# M0519AE_v1 register map
File version: 1.0
Registers are 32-bit, read-write, reset 0x0 unless marked. A register's access mark holds for its fields unless they carry their own. Offsets are from the block's base; [hi:lo] are bit positions; {n}, {i} and the like mark numbered series.

## UART0 — UART Register Map
Base 0x40050000
Same registers: UART1 0x40150000
0x00 UA_RBR ro reset not defined — UART Receive Buffer Register
  [7:0] RBR — Receive Buffer Register (Read Only). By reading this register, the UART will return an 8-bit data received from UART_RXD pin (LSB first).
0x00 UA_THR wo reset not defined (alternate view of UA_RBR) — UART Transmit Holding Register
  [7:0] THR — Transmit Holding Register. By writing one byte to this register, the data byte will be stored in transmitter FIFO. The UART Controller will send out the data stored in transmitter FIFO top location through the UART_TXD pin. (LSB first)
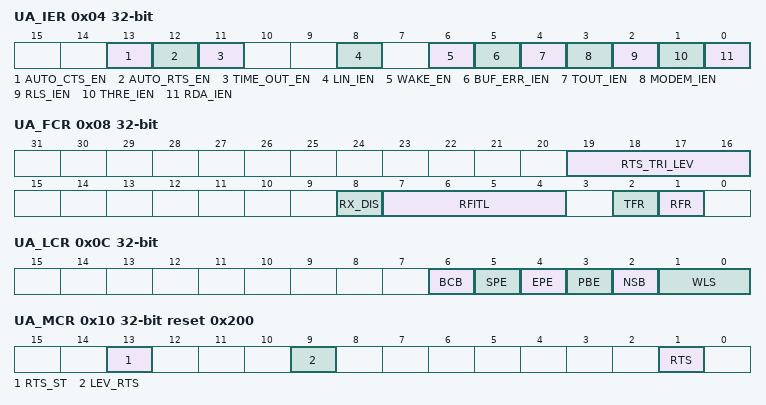
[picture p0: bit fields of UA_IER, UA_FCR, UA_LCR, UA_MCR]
0x04 UA_IER — UART Interrupt Enable Register
  [13] AUTO_CTS_EN — nCTS Auto Flow Control Enable Bit. When nCTS auto-flow is enabled, the UART will send data to external device when nCTS input assert (UART will not send data to device until nCTS is asserted).
    0=nCTS auto-flow control Disabled; 1=nCTS auto-flow control Enabled
  [12] AUTO_RTS_EN — nRTS Auto Flow Control Enable Bit. When nRTS auto-flow is enabled, if the number of bytes in the RX FIFO equals the RTS_TRI_LEV (UA_FCR[19:16]), the UART will de-assert nRTS signal.
    0=nRTS auto-flow control Disabled; 1=nRTS auto-flow control Enabled
  [11] TIME_OUT_EN — Receive Buffer Time Out Counter Enable Bit
    0=Receive Buffer time out counter Disabled; 1=Receive Buffer time out counter Enabled
  [8] LIN_IEN — LIN Bus Interrupt Enable Bit. Note: This field is used for LIN function mode.
    0=Lin bus interrupt Disabled; 1=Lin bus interrupt Enabled
  [6] WAKE_EN — UART Wake-up Function Enable Bit
    0=UART wake-up function Disabled; 1=UART wake-up function Enabled, when the chip is in Power-down mode, an external nCTS change will wake-up chip from Power-down mode
  [5] BUF_ERR_IEN — Buffer Error Interrupt Enable Bit
    0=Buffer error interrupt Disabled; 1=Buffer error interrupt Enabled
  [4] TOUT_IEN — RX Time Out Interrupt Enable Bit
    0=RX time-out interrupt Disabled; 1=RX time-out interrupt Enabled
  [3] MODEM_IEN — Modem Status Interrupt Enable Bit
    0=Modem status interrupt Disabled; 1=Modem status interrupt Enabled
  [2] RLS_IEN — Receive Line Status Interrupt Enable Bit
    0=Receive Line Status interrupt Disabled; 1=Receive Line Status interrupt Enabled
  [1] THRE_IEN — Transmit Holding Register Empty Interrupt Enable Bit
    0=Transmit holding register empty interrupt Disabled; 1=Transmit holding register empty interrupt Enabled
  [0] RDA_IEN — Receive Data Available Interrupt Enable Bit
    0=Receive data available interrupt Disabled; 1=Receive data available interrupt Enabled
0x08 UA_FCR — UART FIFO Control Register
  [19:16] RTS_TRI_LEV — nRTS Trigger Level for Auto-flow Control Use. Note: This field is used for auto nRTS flow control.
    0=nRTS Trigger Level is 1 byte; 1=nRTS Trigger Level is 4 bytes; 2=nRTS Trigger Level is 8 bytes; 3=nRTS Trigger Level is 14 bytes
  [8] RX_DIS — Receiver Disable Register. The receiver is disabled or not (set 1 to disable receiver). Note: This field is used for RS-485 Normal Multi-drop mode. It should be programmed before RS485_NMM (UA_ALT_CSR [8]) is programmed.
    0=Receiver Enabled; 1=Receiver Disabled
  [7:4] RFITL — RX FIFO Interrupt Trigger Level. When the number of bytes in the receive FIFO equals the RFITL, the RDA_IF will be set (if RDA_IEN(UA_IER [0]) enabled, and an interrupt will be generated).
    0=RX FIFO Interrupt Trigger Level is 1 byte; 1=RX FIFO Interrupt Trigger Level is 4 bytes; 2=RX FIFO Interrupt Trigger Level is 8 bytes; 3=RX FIFO Interrupt Trigger Level is 14 bytes
  [2] TFR — TX Field Software Reset. When TFR is set, all the byte in the transmit FIFO and TX internal state machine are cleared. Note: This bit will automatically clear at least 3 UART engine clock cycles.
    0=No effect; 1=Reset the TX internal state machine and pointers
  [1] RFR — RX Field Software Reset. When RFR is set, all the byte in the receiver FIFO and RX internal state machine are cleared. Note: This bit will automatically clear at least 3 UART engine clock cycles.
    0=No effect; 1=Reset the RX internal state machine and pointers
0x0C UA_LCR — UART Line Control Register
  [6] BCB — Break Control Bit. Note: When this bit is set to logic 1, the serial data output (TX) is forced to the Spacing State (logic 0). This bit acts only on TX and has no effect on the transmitter logic.
    0=Break Control Disabled; 1=Break Control Enabled
  [5] SPE — Stick Parity Enable Bit. Note: If PBE (UA_LCR[3]) and EBE (UA_LCR[4]) are logic 1, the parity bit is transmitted and checked as logic 0. If PBE (UA_LCR[3]) is 1 and EBE (UA_LCR[4]) is 0 then the parity bit is transmitted and checked as 1.
    0=Stick parity Disabled; 1=Stick parity Enabled
  [4] EPE — Even Parity Enable Bit. Note: This bit has effect only when PBE (UA_LCR[3]) is set.
    0=Odd number of logic 1's is transmitted and checked in each word; 1=Even number of logic 1's is transmitted and checked in each word
  [3] PBE — Parity Bit Enable Bit. Note: Parity bit is generated on each outgoing character and is checked on each incoming data.
    0=No parity bit; 1=Parity bit generated Enabled
  [2] NSB — Number of "STOP Bit"
    0=One " STOP bit" is generated in the transmitted data; 1=When select 5-bit word length, 1.5 "STOP bit" is generated in the transmitted data. When select 6-,7- and 8-bit word length, 2 "STOP bit" is generated in the transmitted data
  [1:0] WLS — Word Length Selection
    {v}=character length is {v+5}-bit (v=0..3)
0x10 UA_MCR reset 0x200 — UART Modem Control Register
  [13] RTS_ST ro — nRTS Pin State (Read Only). This bit mirror from nRTS pin output of voltage logic status.
    0=nRTS pin output is low level voltage logic state; 1=nRTS pin output is high level voltage logic state
  [9] LEV_RTS — nRTS Pin Active Level. This bit defines the active level state of nRTS pin output. Note1: Refer to Figure 678 and Figure 679 for UART function mode. Note2: Refer to Figure 682 and Figure 683 for RS-485 function mode.
    0=nRTS pin output is high level active; 1=nRTS pin output is low level active. (Default)
  [1] RTS — nRTS (Request-to-send) Signal. This bit is direct control internal nRTS signal active or not, and then drive the nRTS pin output with LEV_RTS bit configuration. Note1: This nRTS signal control bit is not effective when nRTS auto-flow control is enabled in UART function mode. Note2: This nRTS signal control bit is not effective when RS-485 auto direction mode (AUD) is enabled in RS-485 function mode.
    0=nRTS signal is active; 1=nRTS signal is inactive
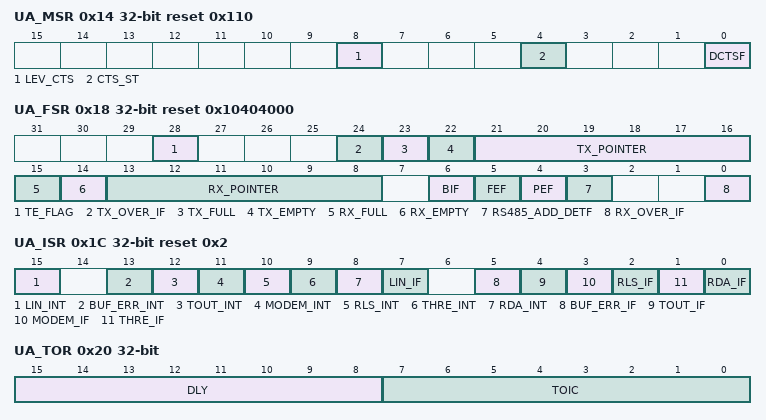
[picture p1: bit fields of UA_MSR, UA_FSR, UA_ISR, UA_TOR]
0x14 UA_MSR reset 0x110 — UART Modem Status Register
  [8] LEV_CTS — nCTS Pin Active Level. This bit defines the active level state of nCTS pin input.
    0=nCTS pin input is high level active; 1=nCTS pin input is low level active. (Default)
  [4] CTS_ST ro — nCTS Pin Status (Read Only). This bit mirror from nCTS pin input of voltage logic status. Note: This bit echoes when UART Controller peripheral clock is enabled, and nCTS multi-function port is selected.
    0=nCTS pin input is low level voltage logic state; 1=nCTS pin input is low level voltage logic state
  [0] DCTSF — Detect nCTS State Change Flag. This bit is set whenever nCTS input has change state, and it will generate Modem interrupt to CPU when MODEM_IEN (UA_IER[3]) is set to 1. Write 1 to clear this bit to 0
0x18 UA_FSR reset 0x10404000 — UART FIFO Status Register
  [28] TE_FLAG ro — Transmitter Empty Flag (Read Only). This bit is set by hardware when TX FIFO (UA_THR) is empty and the STOP bit of the last byte has been transmitted. Note: This bit is cleared automatically when TX FIFO is not empty or the last byte transmission has not completed.
    0=TX FIFO is not empty or the STOP bit of the last byte has not been transmitted; 1=TX FIFO is empty and the STOP bit of the last byte has been transmitted
  [24] TX_OVER_IF — TX Overflow Error Interrupt Flag. If TX FIFO (UA_THR) is full, an additional write to UA_THR will cause this bit to logic 1. Note: This bit can be cleared by writing '1' to it.
    0=TX FIFO is not overflow; 1=TX FIFO is overflow
  [23] TX_FULL ro — Transmitter FIFO Full (Read Only). This bit indicates TX FIFO is full or not. Note: This bit is set when the number of usage in TX FIFO Buffer equal to 16, otherwise it is cleared by hardware.
    0=TX FIFO is not full; 1=TX FIFO is full
  [22] TX_EMPTY ro — Transmitter FIFO Empty (Read Only). This bit indicates TX FIFO is empty or not. Note: When the last byte of TX FIFO has been transferred to Transmitter Shift Register, hardware sets this bit high. It will be cleared when writing data into UA_THR (TX FIFO not empty).
    0=TX FIFO is not empty; 1=TX FIFO is empty
  [21:16] TX_POINTER ro — TX FIFO Pointer (Read Only). This field indicates the TX FIFO Buffer Pointer. When CPU writes one byte into UA_THR, TX_POINTER increases one. When one byte of TX FIFO is transferred to Transmitter Shift Register, TX_POINTER decreases one. The Maximum value shown in TX_POINTER is 15. When the using level of TX FIFO Buffer equal to 16, the TX_FULL bit is set to 1 and TX_POINTER will show 0. As one byte of TX FIFO is transferred to Transmitter Shift Register, the TX_FULL bit is cleared to 0 and TX_POINTER will show 15.
  [15] RX_FULL ro — Receiver FIFO Full (Read Only). This bit indicates RX FIFO is full or not. Note: This bit is set when the number of usage in RX FIFO Buffer is equal to 16, otherwise is cleared by hardware.
    0=RX FIFO is not full; 1=RX FIFO is full
  [14] RX_EMPTY ro — Receiver FIFO Empty (Read Only). This bit indicates RX FIFO empty or not. Note: When the last byte of RX FIFO has been read by CPU, hardware sets this bit high. It will be cleared when UART receives any new data.
    0=RX FIFO is not empty; 1=RX FIFO is empty
  [13:8] RX_POINTER ro — RX FIFO Pointer (Read Only). This field indicates the RX FIFO Buffer Pointer. When UART receives one byte from external device, RX_POINTER increases one. When one byte of RX FIFO is read by CPU, RX_POINTER decreases one. The Maximum value shown in RX_POINTER is 15. When the using level of RX FIFO Buffer equal to 16, the RX_FULL bit is set to 1 and RX_POINTER will show 0. As one byte of RX FIFO is read by CPU, the RX_FULL bit is cleared to 0 and RX_POINTER will show 15.
  [6] BIF — Break Error Interrupt Flag. This bit is set to a logic 1 whenever the received data input(RX) is held in the "spacing state" (logic 0) for longer than a full word transmission time (that is, the total time of "start bit" + data bits + parity + stop bits). Note: This bit can be cleared by writing '1' to it.
    0=No Break error is generated; 1=Break error is generated
  [5] FEF — Frame Error Flag. This bit is set to logic 1 whenever the received character does not have a valid "stop bit" (that is, the stop bit following the last data bit or parity bit is detected as a logic 0). Note: This bit can be cleared by writing '1' to it.
    0=No frame error is generated; 1=Frame error is generated
  [4] PEF — Parity Error Flag. This bit is set to logic 1 whenever the received character does not have a valid "parity bit" . Note: This bit can be cleared by writing '1' to it.
    0=No parity error is generated; 1=Parity error is generated
  [3] RS485_ADD_DETF — RS-485 Address Byte Detection Flag. Note1: This field is used for RS-485 function mode and RS485_ADD_EN (UA_ALT_CSR[15]) is set to 1 to enable Address detection mode. Note2: This bit can be cleared by writing '1' to it.
    0=Receiver detects a data that is not an address bit (bit 9 ='0'); 1=Receiver detects a data that is an address bit (bit 9 ='1')
  [0] RX_OVER_IF — RX Overflow Error Interrupt Flag. This bit is set when RX FIFO overflow. If the number of bytes of received data is greater than RX_FIFO (UA_RBR) size, this bit will be set. Note: This bit can be cleared by writing '1' to it.
    0=RX FIFO is not overflow; 1=RX FIFO is overflow
0x1C UA_ISR reset 0x2 — UART Interrupt Status Register
  [15] LIN_INT ro — LIN Bus Interrupt Indicator (Read Only). This bit is set if LIN_IEN (UA_IER[8]) and LIN _IF (UA_ISR[7]) are both set to 1.
    0=No LIN Bus interrupt is generated; 1=The LIN Bus interrupt is generated
  [13] BUF_ERR_INT ro — Buffer Error Interrupt Indicator (Read Only). This bit is set if BUF_ERR_IEN (UA_IER[5]) and BUF_ERR_IF (UA_ISR[5]) are both set to 1.
    0=No buffer error interrupt is generated; 1=Buffer error interrupt is generated
  [12] TOUT_INT ro — Time Out Interrupt Indicator (Read Only). This bit is set if TOUT_IEN (UA_IER[4]) and TOUT_IF (UA_ISR[4]) are both set to 1.
    0=No time-out interrupt is generated; 1=Time-out interrupt is generated
  [11] MODEM_INT ro — MODEM Status Interrupt Indicator (Read Only). This bit is set if MODEM_IEN (UA_IER[3]) and MODEM_IF (UA_ISR[3]) are both set to 1.
    0=No Modem interrupt is generated; 1=Modem interrupt is generated
  [10] RLS_INT ro — Receive Line Status Interrupt Indicator (Read Only). This bit is set if RLS_IEN (UA_IER[2] and RLS_IF (UA_ISR[2]) are both set to 1.
    0=No RLS interrupt is generated; 1=RLS interrupt is generated
  [9] THRE_INT ro — Transmit Holding Register Empty Interrupt Indicator (Read Only). This bit is set if THRE_IEN (UA_IER[1]) and THRE_IF (UA_ISR[1]) are both set to 1.
    0=No THRE interrupt is generated; 1=THRE interrupt is generated
  [8] RDA_INT ro — Receive Data Available Interrupt Indicator (Read Only). This bit is set if RDA_IEN (UA_IER[0]) and RDA_IF (UA_ISR[0]) are both set to 1.
    0=No RDA interrupt is generated; 1=RDA interrupt is generated
  [7] LIN_IF ro — LIN Bus Flag (Read Only). Note: This bit is read only. This bit is cleared when LINS_HDET_F (UA_LIN_SR[0]), LIN_BKDET_F (UA_LIN_SR[8]), BIT_ERR_F (UA_LIN_SR[9]), LINS_IDPENR_F (UA_LIN_SR[2]) and LINS_HERR_F (UA_LIN_SR[1]) all are cleared.
    0=None of LINS_HDET_F, LIN_BKDET_F, BIT_ERR_F, LINS_IDPERR_F and LINS_HERR_F is generated; 1=At least one of LINS_HDET_F, LIN_BKDET_F, BIT_ERR_F, LINS_IDPERR_F and LINS_HERR_F is generated
  [5] BUF_ERR_IF ro — Buffer Error Interrupt Flag (Read Only). This bit is set when the TX or RX FIFO overflows (TX_OVER_IF (UA_FSR[24]) or RX_OVER_IF (UA_FSR[0]) is set. When BUF_ERR_IF (UA_ISR[5]) is set, the transfer is not correct. If BUF_ERR_IEN (UA_IER [5]) is enabled, the buffer error interrupt will be generated. Note: This bit is cleared if both of RX_OVER_IF (UA_FSR[0]) and TX_OVER_IF (UA_FSR[24]) are cleared to 0 by writing 1 to RX_OVER_IF (UA_FSR[0]) and TX_OVER_IF (UA_FSR[24]).
    0=No buffer error interrupt flag is generated; 1=Buffer error interrupt flag is generated
  [4] TOUT_IF ro — Time Out Interrupt Flag (Read Only). This bit is set when the RX FIFO is not empty and no activities occurred in the RX FIFO and the time out counter equal to TOIC (UA_TOR[7:0]). If TOUT_IEN (UA_IER [4]) is enabled, the time-out interrupt will be generated. Note: User can read UA_RBR (RX is in active) to clear it.
    0=No Time-out interrupt flag is generated; 1=Time-out interrupt flag is generated
  [3] MODEM_IF ro — MODEM Interrupt Flag (Read Only). Note: This bit is reset to 0 when bit DCTSF (UA_MSR[0]) is cleared by a write 1 on DCTSF (UA_MSR[0]).
    0=No Modem interrupt flag is generated; 1=Modem interrupt flag is generated
  [2] RLS_IF ro — Receive Line Interrupt Flag (Read Only). This bit is set when the RX receive data have parity error, frame error or break error (at least one of 3 bits, BIF (UA_FSR[6]), FEF (UA_FSR[5]) and PEF (UA_FSR[4]), is set). If RLS_IEN (UA_IER [2]) is enabled, the RLS interrupt will be generated. Note2: This bit is read only and reset to 0 when all bits of BIF (UA_FSR[6]), FEF (UA_FSR[5]) and PEF (UA_FSR[4]) are cleared. Note3: In RS-485 function mode, this bit is read only and reset to 0 when all bits of BIF (UA_FSR[6]) , FEF(UA_FSR[5]) and PEF(UA_FSR[4]) and RS485_ADD_DETF (UA_FSR[3]) are cleared.
    0=No RLS interrupt flag is generated; 1=RLS interrupt flag is generated
  [1] THRE_IF ro — Transmit Holding Register Empty Interrupt Flag (Read Only). This bit is set when the last data of TX FIFO is transferred to Transmitter Shift Register. If THRE_IEN (UA_IER [1]) is enabled, the THRE interrupt will be generated. Note: This bit is read only and it will be cleared when writing data into THR (TX FIFO not empty).
    0=No THRE interrupt flag is generated; 1=THRE interrupt flag is generated
  [0] RDA_IF ro — Receive Data Available Interrupt Flag (Read Only). When the number of bytes in the RX FIFO equals the RFITL (UA_FCR[7:4]) then the RDA_IF (UA_ISR[0]) will be set. If RDA_IEN (UA_IER [0]) is enabled, the RDA interrupt will be generated. Note: This bit is read only and it will be cleared when the number of unread bytes of RX FIFO drops below the threshold level (RFITL (UA_FCR[7:4])).
    0=No RDA interrupt flag is generated; 1=RDA interrupt flag is generated
0x20 UA_TOR — UART Time Out Register
  [15:8] DLY — TX Delay Time Value. This field is used to programming the transfer delay time between the last stop bit and next start bit. The unit is bit time.
  [7:0] TOIC — Time Out Interrupt Comparator
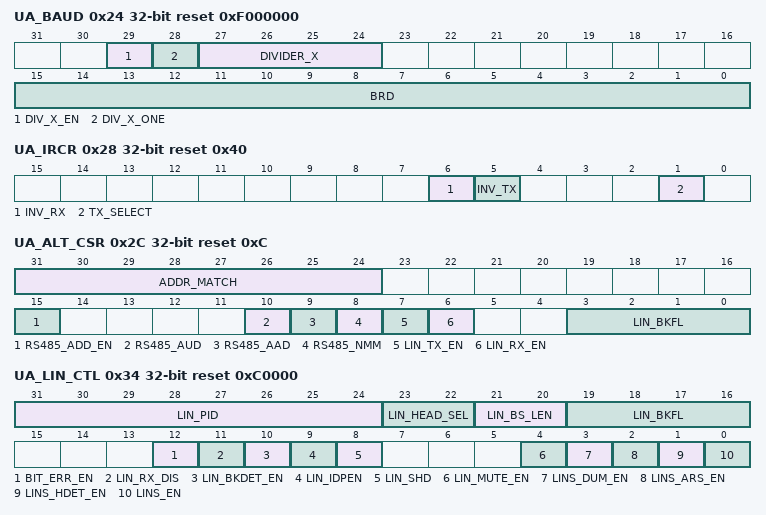
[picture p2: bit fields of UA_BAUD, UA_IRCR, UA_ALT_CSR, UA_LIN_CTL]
0x24 UA_BAUD reset 0xF000000 — UART Baud Rate Divisor Register
  [29] DIV_X_EN — Divider X Enable Bit. Note1: The detail description is shown in UART Controller Baud Rate Generator section. Note2: In IrDA mode, this bit must disable.
    0=Divider X Disabled (the equation of M = 16); 1=Divider X Enabled (the equation of M = X+1, but DIVIDER_X [27:24] must = 8)
  [28] DIV_X_ONE — Divider X Equal to 1. Note: The detail description is shown in UART Controller Baud Rate Generator section.
    0=Divider M = X+1 (the equation of M = X+1, but DIVIDER_X[27:24] must = 8); 1=Divider M = 1
  [27:24] DIVIDER_X — Divider X. Note 1: This field is used for baud rate calculation in mode 1 and has no effect for baud rate calculation in mode 0 and mode 2. Note 2: The detail description is shown in UART Controller Baud Rate Generator section.
  [15:0] BRD — Baud Rate Divider. The field indicates the baud rate divider. This filed is used in baud rate calculation. Note: The detail description is shown in UART Controller Baud Rate Generator section.
0x28 UA_IRCR reset 0x40 — UART IrDA Control Register
  [6] INV_RX — IrDA Inverse Receive Input Signal
    0=None inverse receiving input signal; 1=Inverse receiving input signal. (Default)
  [5] INV_TX — IrDA Inverse Transmitting Output Signal
    0=None inverse transmitting signal. (Default); 1=Inverse transmitting output signal
  [1] TX_SELECT — IrDA Receiver/Transmitter Selection Enable Bit
    0=IrDA Transmitter Disabled and Receiver Enabled. (Default); 1=IrDA Transmitter Enabled and Receiver Disabled
0x2C UA_ALT_CSR reset 0xC — UART Alternate Control/Status Register
  [31:24] ADDR_MATCH — Address Match Value Register. This field contains the RS-485 address match values. Note: This field is used for RS-485 auto address detection mode.
  [15] RS485_ADD_EN — RS-485 Address Detection Enable Bit. This bit is used to enable RS-485 Address Detection mode. Note: This field is used for RS-485 any operation mode.
    0=Address detection mode Disabled; 1=Address detection mode Enabled
  [10] RS485_AUD — RS-485 Auto Direction Mode (AUD). Note: It can be active with RS-485_AAD or RS-485_NMM operation mode.
    0=RS-485 Auto Direction Operation mode (AUO) Disabled; 1=RS-485 Auto Direction Operation mode (AUO) Enabled
  [9] RS485_AAD — RS-485 Auto Address Detection Operation Mode (AAD). Note: It cannot be active with RS-485_NMM operation mode.
    0=RS-485 Auto Address Detection Operation mode (AAD) Disabled; 1=RS-485 Auto Address Detection Operation mode (AAD) Enabled
  [8] RS485_NMM — RS-485 Normal Multi-drop Operation Mode (NMM). Note: It cannot be active with RS-485_AAD operation mode.
    0=RS-485 Normal Multi-drop Operation mode (NMM) Disabled; 1=RS-485 Normal Multi-drop Operation mode (NMM) Enabled
  [7] LIN_TX_EN — LIN TX Break Mode Enable Bit. Note: When TX break field transfer operation finished, this bit will be cleared automatically.
    0=LIN TX Break mode Disabled; 1=LIN TX Break mode Enabled
  [6] LIN_RX_EN — LIN RX Enable Bit
    0=LIN RX mode Disabled; 1=LIN RX mode Enabled
  [3:0] LIN_BKFL — UART LIN Break Field Length. This field indicates a 4-bit LIN TX break field count. Note1: This break field length is UA_LIN_BKFL + 1.
0x30 UA_FUN_SEL — UART Function Select Register
  [1:0] FUN_SEL — Function Select Enable Bit
    0=UART function Enabled; 1=LIN function Enabled; 2=IrDA function Enabled; 3=RS-485 function Enabled
0x34 UA_LIN_CTL reset 0xC0000 — UART LIN Control Register
  [31:24] LIN_PID — LIN PID Register. This field contains the LIN frame ID value when in LIN function mode, the frame ID parity can be generated by software or hardware depends on LIN_IDPEN (UA_LIN_CTL[9]). . Note1: User can filled any 8-bit value to this field and the bit 24 indicates ID0 (LSB first). Note2: This field can be used for LIN master mode or slave mode.
  [23:22] LIN_HEAD_SEL — LIN Header Select
    0=The LIN header includes "break field"; 1=The LIN header includes "break field" and "sync field"; 2=The LIN header includes "break field", "sync field" and "frame ID field"
  [21:20] LIN_BS_LEN — LIN Break/Sync Delimiter Length . Note: This bit is used for LIN master to sending header field.
    0=The LIN break/sync delimiter length is 1 bit time; 2=The LIN break/sync delimiter length is 2 bit time. The LIN break/sync delimiter length is 3 bit time; 3=The LIN break/sync delimiter length is 4 bit time
  [19:16] LIN_BKFL — LIN Break Field Length. This field indicates a 4-bit LIN TX break field count. Note1: These registers are shadow registers of LIN_BKFL (UA_ALT_CSR[19:16]), User can read/write it by setting LIN_BKFL (UA_ALT_CSR[3:0]) or LIN_BKFL (UA_LIN_CTL[19:16]). Note2: This break field length is LIN_BKFL + 1.
  [12] BIT_ERR_EN — Bit Error Detect Enable Bit
    0=Bit error detection function Disabled; 1=Bit error detection Enabled
  [11] LIN_RX_DIS — LIN Receiver Disable Bit
    0=LIN receiver Enabled; 1=LIN receiver Disabled
  [10] LIN_BKDET_EN — LIN Break Detection Enable Bit
    0=LIN break detection Disabled; 1=LIN break detection Enabled
  [9] LIN_IDPEN — LIN ID Parity Enable Bit
    0=LIN frame ID parity Disabled; 1=LIN frame ID parity Enabled
  [8] LIN_SHD — LIN TX Send Header Enable Bit. The LIN TX header can be "break field" or "break and sync field" or "break, sync and frame ID field", it is depend on setting LIN_HEAD_SEL (UA_LIN_CTL[23:22]). Note1: These registers are shadow registers of LIN_TX_EN (UA_ALT_CSR[7]); user can read/write it by setting LIN_TX_EN (UA_ALT_CSR[7]) or LIN_SHD (UA_LIN_CTL[8]). Note2: When transmitter header field (it may be "break" or "break + sync" or "break + sync + frame ID" selected by LIN_HEAD_SEL (UA_LIN_CTL[23:22]) field) transfer operation finished, this bit will be cleared automatically.
    0=Send LIN TX header Disabled; 1=Send LIN TX header Enabled
  [4] LIN_MUTE_EN — LIN Mute Mode Enable Bit. Note: The exit from mute mode condition and each control and interactions of this field are explained in LIN slave mode.
    0=LIN mute mode Disabled; 1=LIN mute mode Enabled
  [3] LINS_DUM_EN — LIN Slave Divider Update Method Enable Bit. Note2: This bit is used for LIN Slave Automatic Resynchronization mode. (for Non-Automatic Resynchronization mode, this bit should be kept cleared). Note3: The control and interactions of this field are explained in 6.12.5.9.4 (Slave mode with automatic resynchronization).
    0=UA_BAUD updated is writing by software (if no automatic resynchronization update occurs at the same time); 1=UA_BAUD is updated at the next received character. User must set the bit before checksum reception
  [2] LINS_ARS_EN — LIN Slave Automatic Resynchronization Mode Enable Bit. Note2: When operation in Automatic Resynchronization mode, the baud rate setting must be mode2 (DIV_X_EN (UA_BAUD [29]) and DIV_X_ONE (UA_BAUD [28]) must be 1). Note3: The control and interactions of this field are explained in 6.12.5.9.4 (Slave mode with automatic resynchronization).
    0=LIN automatic resynchronization Disabled; 1=LIN automatic resynchronization Enabled
  [1] LINS_HDET_EN — LIN Slave Header Detection Enable Bit
    0=LIN slave header detection Disabled; 1=LIN slave header detection Enabled
  [0] LINS_EN — LIN Slave Mode Enable Bit
    0=LIN slave mode Disabled; 1=LIN slave mode Enabled
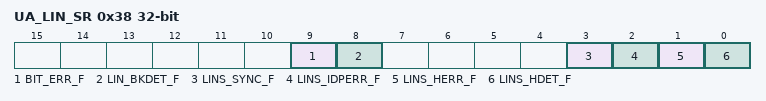
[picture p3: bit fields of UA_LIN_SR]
0x38 UA_LIN_SR — UART LIN Status Register
  [9] BIT_ERR_F — Bit Error Detect Status Flag. At TX transfer state, hardware will monitoring the bus state, if the input pin (SIN) state not equals to the output pin (SOUT) state, BIT_ERR_F (UA_LIN_SR[9]) will be set.
  [8] LIN_BKDET_F — LIN Break Detection Flag. This bit is set by hardware when a break is detected and be cleared by writing 1 to it.
    0=LIN break not detected; 1=LIN break detected
  [3] LINS_SYNC_F — LIN Slave Sync Field. This bit indicates that the LIN sync field is being analyzed in automatic resynchronization mode. When the receiver header have some error been detect, user must to reset the internal circuit to re-search new frame header by writing 1 to this bit. Note2: This bit is cleared by writing 1 to it. Note3: When user writing 1 to it, hardware will reload the initial baud-rate and re-search new frame header.
    0=The current character is not at LIN sync state; 1=The current character is at LIN sync state
  [2] LINS_IDPERR_F — LIN Slave ID Parity Error Flag. This bit is set by hardware when receipted frame ID parity is not correct.
    0=no active; 1=Receipted frame ID parity is not correct
  [1] LINS_HERR_F — LIN Slave Header Error Flag. This bit is set by hardware when a LIN header error is detected in LIN slave mode and be cleared by writing 1 to it. The header errors include "break delimiter is too short", "frame error in sync field or Identifier field", "sync field data is not 0x55 without automatic resynchronization mode", "sync field deviation error with automatic resynchronization mode", "sync field measure time-out with automatic resynchronization mode" and "LIN header reception time-out".
    0=LIN header error not detected; 1=LIN header error detected
  [0] LINS_HDET_F — LIN Slave Header Detection Flag. This bit is set by hardware when a LIN header is detected in LIN slave mode and be cleared by writing 1 to it.
    0=LIN header not detected; 1=LIN header detected (break + sync + frame ID)
